# STM32GBK1CBT6 register map
File version: 2.1
CPU: CM4 r0p1, little endian, MPU, FPU, 4 interrupt priority bits
Registers are 32-bit, read-write, reset 0x0 unless marked. A register's access mark holds for its fields unless they carry their own. Offsets are from the block's base; [hi:lo] are bit positions; {n}, {i} and the like mark numbered series.

## ADC12_Common — Analog-to-Digital Converter
Base 0x50000300
Same registers: ADC345_Common 0x50000700
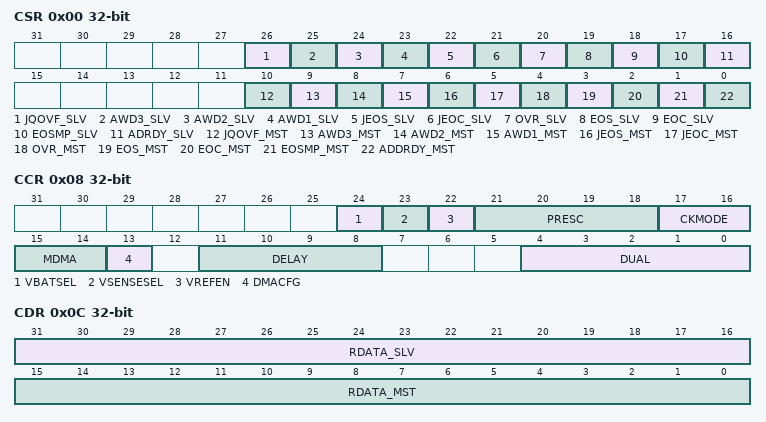
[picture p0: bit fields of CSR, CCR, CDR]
0x00 CSR ro — ADC Common status register
  [26] JQOVF_SLV — Injected Context Queue Overflow flag of the slave ADC
  [25] AWD3_SLV — Analog watchdog 3 flag of the slave ADC
  [24] AWD2_SLV — Analog watchdog 2 flag of the slave ADC
  [23] AWD1_SLV — Analog watchdog 1 flag of the slave ADC
  [22] JEOS_SLV — End of injected sequence flag of the slave ADC
  [21] JEOC_SLV — End of injected conversion flag of the slave ADC
  [20] OVR_SLV — Overrun flag of the slave ADC
  [19] EOS_SLV — End of regular sequence flag of the slave ADC
  [18] EOC_SLV — End of regular conversion of the slave ADC
  [17] EOSMP_SLV
  [16] ADRDY_SLV
  [10] JQOVF_MST
  [9] AWD3_MST
  [8] AWD2_MST
  [7] AWD1_MST
  [6] JEOS_MST
  [5] JEOC_MST
  [4] OVR_MST
  [3] EOS_MST
  [2] EOC_MST
  [1] EOSMP_MST
  [0] ADDRDY_MST
0x08 CCR — ADC common control register
  [24] VBATSEL — VBAT selection
  [23] VSENSESEL — VTS selection
  [22] VREFEN — VREFINT enable
  [21:18] PRESC — ADC prescaler
  [17:16] CKMODE — ADC clock mode
  [15:14] MDMA — Direct memory access mode for multi ADC mode
  [13] DMACFG — DMA configuration (for multi-ADC mode)
  [11:8] DELAY — Delay between 2 sampling phases
  [4:0] DUAL — Dual ADC mode selection
0x0C CDR ro — ADC common regular data register for dual and triple modes
  [31:16] RDATA_SLV — Regular data of the slave ADC
  [15:0] RDATA_MST — Regular data of the master ADC

## FMAC — Filter Math Accelerator
Base 0x40021400
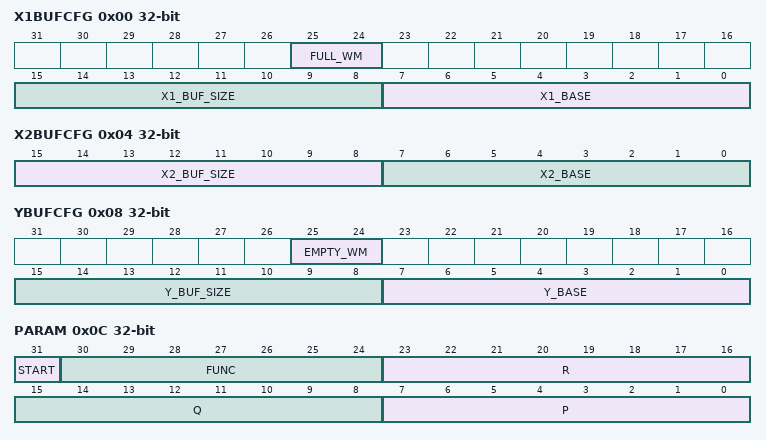
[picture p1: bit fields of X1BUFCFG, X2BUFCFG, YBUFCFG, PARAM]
0x00 X1BUFCFG — FMAC X1 Buffer Configuration register
  [25:24] FULL_WM, [15:8] X1_BUF_SIZE, [7:0] X1_BASE
0x04 X2BUFCFG — FMAC X2 Buffer Configuration register
  [15:8] X2_BUF_SIZE — X1_BUF_SIZE
  [7:0] X2_BASE — X1_BASE
0x08 YBUFCFG — FMAC Y Buffer Configuration register
  [25:24] EMPTY_WM
  [15:8] Y_BUF_SIZE — X1_BUF_SIZE
  [7:0] Y_BASE — X1_BASE
0x0C PARAM — FMAC Parameter register
  [31] START, [30:24] FUNC, [23:16] R, [15:8] Q, [7:0] P
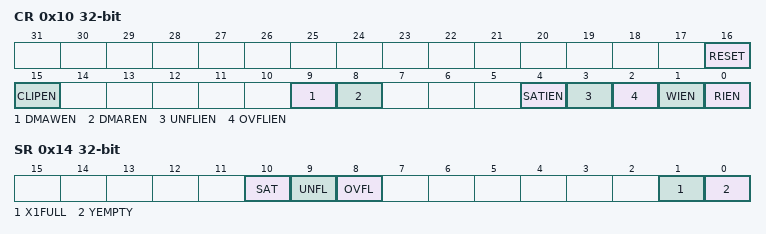
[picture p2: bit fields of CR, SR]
0x10 CR — FMAC Control register
  [16] RESET, [15] CLIPEN, [9] DMAWEN, [8] DMAREN, [4] SATIEN, [3] UNFLIEN, [2] OVFLIEN, [1] WIEN, [0] RIEN
0x14 SR ro — FMAC Status register
  [10] SAT, [9] UNFL, [8] OVFL, [1] X1FULL, [0] YEMPTY
0x18 WDATA wo — FMAC Write Data register
  [15:0] WDATA
0x1C RDATA ro — FMAC Read Data register
  [15:0] RDATA

## CORDIC — CORDIC Co-processor
Base 0x40020C00
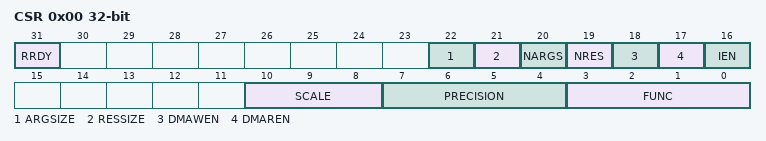
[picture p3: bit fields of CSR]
0x00 CSR — CORDIC Control Status register
  [31] RRDY, [22] ARGSIZE, [21] RESSIZE, [20] NARGS, [19] NRES, [18] DMAWEN, [17] DMAREN, [16] IEN, [10:8] SCALE, [7:4] PRECISION, [3:0] FUNC
0x04 WDATA — FMAC Write Data register
  [31:0] ARG
0x08 RDATA ro — FMAC Read Data register
  [31:0] RES

## TAMP — Tamper and backup registers
Base 0x40002400
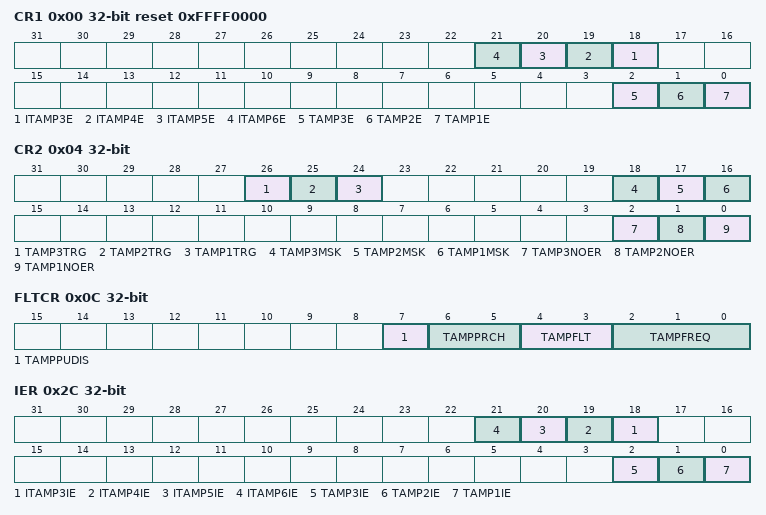
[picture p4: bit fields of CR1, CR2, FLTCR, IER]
0x00 CR1 reset 0xFFFF0000 — control register 1
  [n+15] ITAMP{n}E (n=3..6)
  [2] TAMP3E — TAMP2E
  [1] TAMP2E
  [0] TAMP1E
0x04 CR2 — control register 2
  [26] TAMP3TRG, [25] TAMP2TRG, [24] TAMP1TRG, [18] TAMP3MSK, [17] TAMP2MSK, [16] TAMP1MSK, [2] TAMP3NOER, [1] TAMP2NOER, [0] TAMP1NOER
0x0C FLTCR — TAMP filter control register
  [7] TAMPPUDIS, [6:5] TAMPPRCH, [4:3] TAMPFLT, [2:0] TAMPFREQ
0x2C IER — TAMP interrupt enable register
  [n+15] ITAMP{n}IE (n=3..6), [2] TAMP3IE, [1] TAMP2IE, [0] TAMP1IE
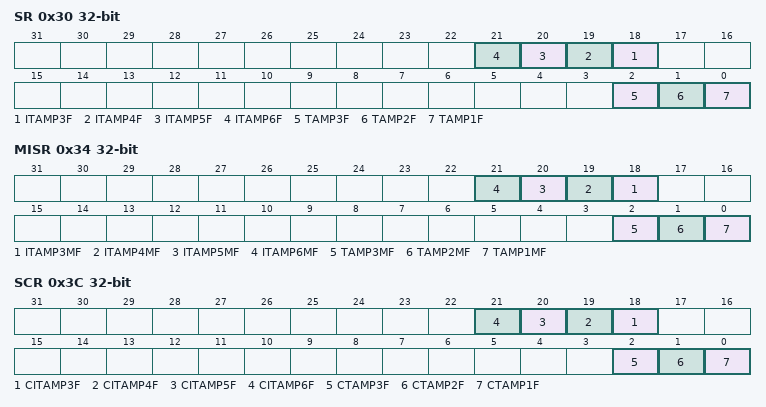
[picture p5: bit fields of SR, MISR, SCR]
0x30 SR ro — TAMP status register
  [n+15] ITAMP{n}F (n=3..6), [2] TAMP3F, [1] TAMP2F, [0] TAMP1F
0x34 MISR ro — TAMP masked interrupt status register
  [n+15] ITAMP{n}MF (n=3..6), [2] TAMP3MF, [1] TAMP2MF, [0] TAMP1MF
0x3C SCR — TAMP status clear register
  [n+15] CITAMP{n}F (n=3..6), [2] CTAMP3F, [1] CTAMP2F, [0] CTAMP1F
{0x100+4i} BKP{i}R (i=0..31) — TAMP backup register
  [31:0] BKP

## UCPD1
Base 0x4000A000
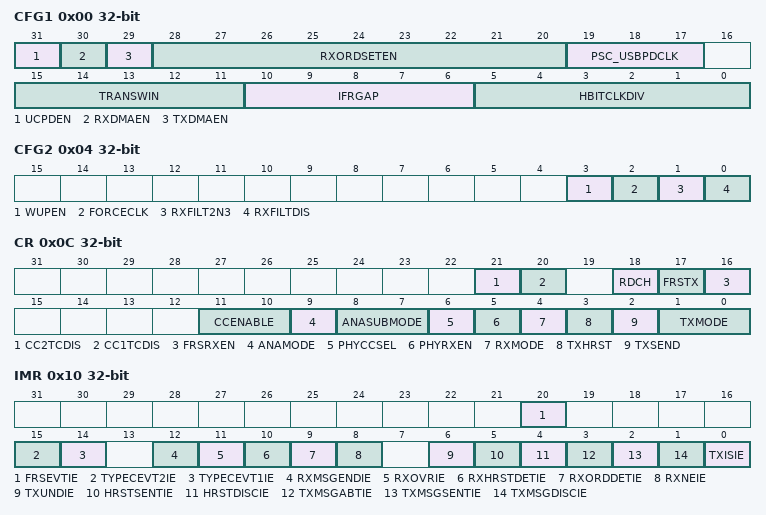
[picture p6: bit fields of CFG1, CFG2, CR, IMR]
0x00 CFG1 — UCPD configuration register 1
  [31] UCPDEN, [30] RXDMAEN, [29] TXDMAEN, [28:20] RXORDSETEN, [19:17] PSC_USBPDCLK, [15:11] TRANSWIN, [10:6] IFRGAP, [5:0] HBITCLKDIV
0x04 CFG2 — UCPD configuration register 2
  [3] WUPEN, [2] FORCECLK, [1] RXFILT2N3, [0] RXFILTDIS
0x0C CR — UCPD configuration register 2
  [21] CC2TCDIS, [20] CC1TCDIS, [18] RDCH, [17] FRSTX, [16] FRSRXEN, [11:10] CCENABLE, [9] ANAMODE, [8:7] ANASUBMODE, [6] PHYCCSEL, [5] PHYRXEN, [4] RXMODE, [3] TXHRST, [2] TXSEND, [1:0] TXMODE
0x10 IMR — UCPD Interrupt Mask Register
  [20] FRSEVTIE, [15] TYPECEVT2IE, [14] TYPECEVT1IE, [12] RXMSGENDIE, [11] RXOVRIE, [10] RXHRSTDETIE, [9] RXORDDETIE, [8] RXNEIE, [6] TXUNDIE, [5] HRSTSENTIE, [4] HRSTDISCIE, [3] TXMSGABTIE, [2] TXMSGSENTIE, [1] TXMSGDISCIE, [0] TXISIE
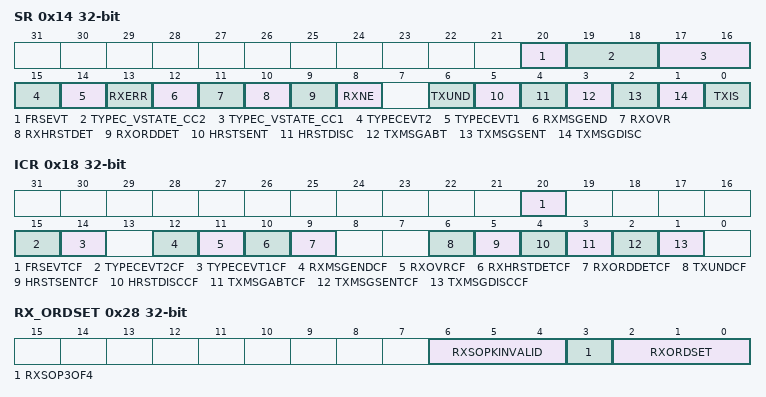
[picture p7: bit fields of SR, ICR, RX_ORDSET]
0x14 SR — UCPD Status Register
  [20] FRSEVT, [19:18] TYPEC_VSTATE_CC2, [17:16] TYPEC_VSTATE_CC1, [15] TYPECEVT2, [14] TYPECEVT1, [13] RXERR, [12] RXMSGEND, [11] RXOVR, [10] RXHRSTDET, [9] RXORDDET, [8] RXNE, [6] TXUND, [5] HRSTSENT, [4] HRSTDISC, [3] TXMSGABT, [2] TXMSGSENT, [1] TXMSGDISC, [0] TXIS
0x18 ICR — UCPD Interrupt Clear Register
  [20] FRSEVTCF, [15] TYPECEVT2CF, [14] TYPECEVT1CF, [12] RXMSGENDCF, [11] RXOVRCF, [10] RXHRSTDETCF, [9] RXORDDETCF, [6] TXUNDCF, [5] HRSTSENTCF, [4] HRSTDISCCF, [3] TXMSGABTCF, [2] TXMSGSENTCF, [1] TXMSGDISCCF
0x1C TX_ORDSET — UCPD Tx Ordered Set Type Register
  [19:0] TXORDSET
0x20 TX_PAYSZ — UCPD Tx Paysize Register
  [9:0] TXPAYSZ
0x24 TXDR — UCPD Tx Data Register
  [7:0] TXDATA
0x28 RX_ORDSET ro — UCPD Rx Ordered Set Register
  [6:4] RXSOPKINVALID, [3] RXSOP3OF4, [2:0] RXORDSET
0x2C RX_PAYSZ ro — UCPD Rx Paysize Register
  [9:0] RXPAYSZ
0x30 RXDR ro — UCPD Rx Data Register
  [7:0] RXDATA
0x34 RX_ORDEXT1 — UCPD Rx Ordered Set Extension Register 1
  [19:0] RXSOPX1
0x38 RX_ORDEXT2 — UCPD Rx Ordered Set Extension Register 2
  [19:0] RXSOPX2

## USB_FS_device
Base 0x40005C00
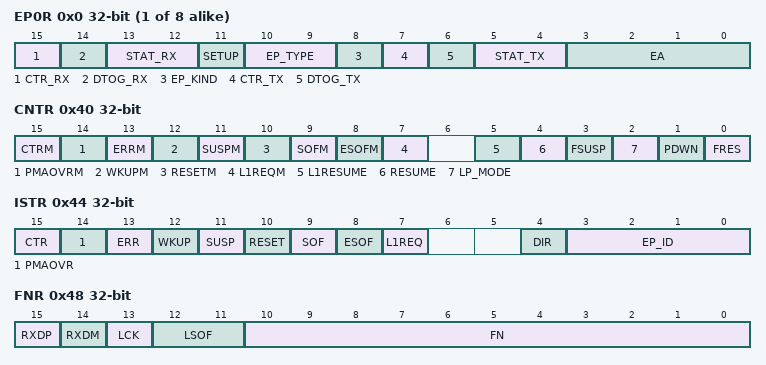
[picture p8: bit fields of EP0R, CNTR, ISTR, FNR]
{0x0+4i} EP{i}R (i=0..7) — USB endpoint n register
  [15] CTR_RX, [14] DTOG_RX, [13:12] STAT_RX, [11] SETUP, [10:9] EP_TYPE, [8] EP_KIND, [7] CTR_TX, [6] DTOG_TX, [5:4] STAT_TX, [3:0] EA
0x40 CNTR — USB control register
  [15] CTRM, [14] PMAOVRM, [13] ERRM, [12] WKUPM, [11] SUSPM, [10] RESETM, [9] SOFM, [8] ESOFM, [7] L1REQM, [5] L1RESUME, [4] RESUME, [3] FSUSP, [2] LP_MODE, [1] PDWN, [0] FRES
0x44 ISTR — USB interrupt status register
  [15] CTR, [14] PMAOVR, [13] ERR, [12] WKUP, [11] SUSP, [10] RESET, [9] SOF, [8] ESOF, [7] L1REQ, [4] DIR, [3:0] EP_ID
0x48 FNR ro — USB frame number register
  [15] RXDP, [14] RXDM, [13] LCK, [12:11] LSOF, [10:0] FN
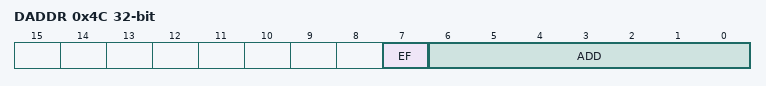
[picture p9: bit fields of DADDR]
0x4C DADDR — USB device address
  [7] EF, [6:0] ADD
0x50 BTABLE — Buffer table address
  [15:3] BTABLE
